# rfc_rat_secure register map
Vendor: Texas Instruments
Peripheral module from a debugger description file (folder CC35X1).
Registers are 32-bit, access per field, reset 0x0 unless marked. A register's access mark holds for its fields unless they carry their own. Offsets are as the file gives them; lines under a group give offsets from that group; [hi:lo] are bit positions; {n}, {i} and the like mark numbered series; 'fields as' and 'values as' point back to an identical list; <NAME> marks a mode.

## rfc_rat_secure
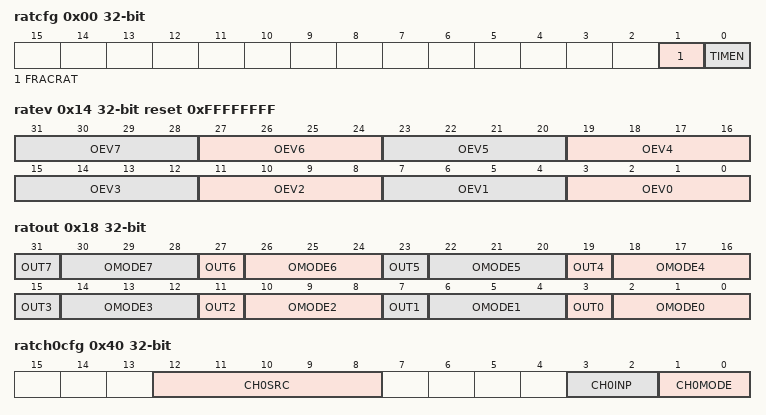
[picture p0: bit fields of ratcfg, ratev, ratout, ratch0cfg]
0x00 ratcfg — Radio Timer Configuration
  [1] FRACRAT rw — Fractional Radio Timer.
    0=DIS (Disable fractional compensation, i.e. use normal timer. Normal RAT tick frequency is the RF Core input clock frequency down-divided by 12 (i.e. typically 48 MHz / 12 = 4 MHz -- giving a RAT tick period of 250 ns).); 1=EN (Enable compensated timer. If the RF Core input clock frequency has a small offset from the expected 48 MHz, the normal divide-by-12 can be replaced with a fractional down-divider to compensate for the skewed input clock and still achieve the normal 4 MHz RAT tick period. With fractional compensation, the RF Core input clock is down-divided by a fractional value (12 + &epsilon;), where &epsilon; is a small adjustment value configured in the RATCOMP register.)
  [0] TIMEN rw — Timer enable.
    0=DIS (Timer is disabled.); 1=EN (Timer is enabled and counter is running.)
0x04 ratcnt rw — Radio Timer Counter Value
  [31:0] CNT — Counter value. This is not writable while radio timer counter is enabled.
0x08 ratadj rw — Radio Timer Adjust Register
  [31:0] ADJ — Value to add to the timer at the next tick. The adjustment value is applied only once. Adjustments can only be performed while the timer is enabled.
0x0C ratarmset — Capture Arm Register
  [7:0] ARM rw — Arm Channel
    0=UNUSED (Writing 0 has no effect); 1=ARM (Channel armed)
0x10 ratarmclr — Capture Arm Clear Register
  [7:0] ARM rw — Arm Channel
    0=DISARM (Channel disarmed); 1=UNUSED (Writing 1 has no effect)
0x14 ratev rw reset 0xFFFFFFFF — Output Event Selector
  [4n+3:4n] OEV{n} (n=4..7) — Output event {n} selector (channel number). This output line goes to RAT GPO line {n-4} in RFC_DBELL:SYSGPOCTL.
  [4n+3:4n] OEV{n} (n=0..3) — Output event {n} selector (channel number).
0x18 ratout — Output Mode Configuration
  [4n+3] OUT{n} ro (n=0..7) — Current value of output line {n}
  [4n+2:4n] OMODE{n} rw (n=0..7) — Output {n} mode
    1=SET (Set output line high on event.); 2=CLR (Set output line low on event.); 3=TGL (Toggle (invert) output line state on event.); 4=LOW (Immediately set output line to low (does not change upon event).); 5=HIGH (Immediately set output line to high (does not change upon event).)
0x1C ratcomp — Timer Compensation Register
  [15:0] RATCOMP rw — Controls fractional compensation of the RAT tick frequency. When fractional compensation is enabled in RATCFG.FRACRAT, the RF Core input clock is divided down by value 12*(1 + RATCOMP/2^21), where RATCOMP is a 16-bit signed value, to still generate the normal tick frequency of 4.0 MHz. This means the fractionally compensated clock divider has a configurable value in range [11.813, 12.187], which means it can compensate for an RF Core input clock frequency in the range [47.250, 48.750] MHz.
0x40 ratch0cfg — Timer Channel 0 Configuration
  [12:8] CH0SRC rw — Identifier of the source used for capture
    31=IMM (Immediate)
  [3:2] CH0INP rw — Input mode
    0=RISE (Capture on rising edge); 1=FALL (Capture on falling edge); 2=BOTH (Capture on both edges)
  [1:0] CH0MODE rw — Channel mode. A mode change will automatically disarm the channel.
    0=DIS (Channel is disabled); 1=COMP (Channel is in compare mode); 2=SINGLECAPT (Channel is in single capture mode); 3=REPEATCAPT (Channel is in repeated capture mode)
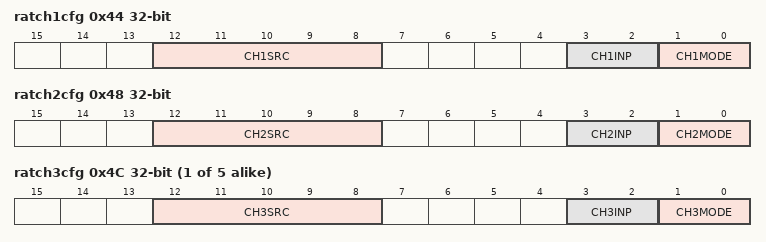
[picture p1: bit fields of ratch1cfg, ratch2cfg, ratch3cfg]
0x44 ratch1cfg — Timer Channel 1 Configuration
  [12:8] CH1SRC rw — Identifier of the source used for capture
    31=IMM (Immediate)
  [3:2] CH1INP rw — Input mode
    values as ratch0cfg.CH0INP
  [1:0] CH1MODE rw — Channel mode
    values as ratch0cfg.CH0MODE
0x48 ratch2cfg — Timer Channel 2 Configuration
  [12:8] CH2SRC rw — Identifier of the source used for capture
    31=IMM (Immediate)
  [3:2] CH2INP rw — Input mode
    0=POSDGE (Capture on rising edge); 1=FALL (Capture on falling edge); 2=BOTH (Capture on both edges)
  [1:0] CH2MODE rw — Channel mode
    values as ratch0cfg.CH0MODE
{0x40+4i} ratch{i}cfg (i=3..7) — Timer Channel {i} Configuration
  [12:8] CH{i}SRC rw — Identifier of the source used for capture
    31=IMM (Immediate)
  [3:2] CH{i}INP rw — Input mode
    values as ratch0cfg.CH0INP
  [1:0] CH{i}MODE rw — Channel mode
    values as ratch0cfg.CH0MODE
{0x80+4i} ratch{i}val rw (i=0..7) — Timer Channel {i} Capture/Compare Register
  [31:0] VAL — Capture/compare value. Only writable when the channel is configured for compare mode. In compare mode, a write to this register will auto-arm the channel.
